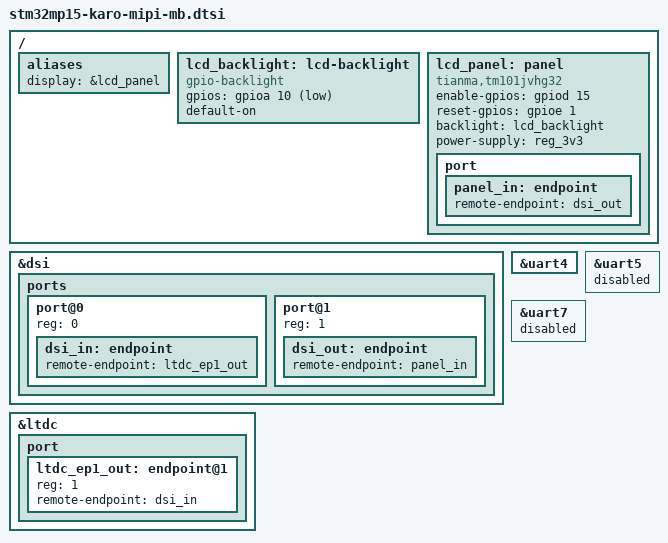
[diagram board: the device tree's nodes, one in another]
// SPDX-License-Identifier: (GPL-2.0 OR BSD-3-Clause)
/*
 * Copyright (C) 2020 Lothar Waßmann <LW@KARO-electronics.de>
 *
 */

/ {
	aliases {
		display = &lcd_panel;
	};

	lcd_backlight: lcd-backlight {
		compatible = "gpio-backlight";
		gpios = <&gpioa 10 GPIO_ACTIVE_LOW>;
		default-on;
	};

	lcd_panel: panel {
		compatible = "tianma,tm101jvhg32";
		pinctrl-names = "default", "sleep";
		enable-gpios = <&gpiod 15 GPIO_ACTIVE_HIGH>;
		reset-gpios = <&gpioe 1 GPIO_ACTIVE_HIGH>;
		backlight = <&lcd_backlight>;
		power-supply = <&reg_3v3>;
		status = "okay";

		port {
			panel_in: endpoint {
				remote-endpoint = <&dsi_out>;
			};
		};
	};
};

&dsi {
	status = "okay";

	ports {
		#address-cells = <1>;
		#size-cells = <0>;

		port@0 {
			reg = <0>;
			dsi_in: endpoint {
				remote-endpoint = <&ltdc_ep1_out>;
			};
		};

		port@1 {
			reg = <1>;
			dsi_out: endpoint {
				remote-endpoint = <&panel_in>;
			};
		};
	};
};

&ltdc {
	status = "okay";

	port {
		#address-cells = <1>;
		#size-cells = <0>;

		ltdc_ep1_out: endpoint@1 {
			reg = <1>;
			remote-endpoint = <&dsi_in>;
		};
	};
};

&uart4 {
	/delete-property/ rts-gpios;
};

&uart5 {
	status = "disabled";
};

&uart7 {
	status = "disabled";
};
